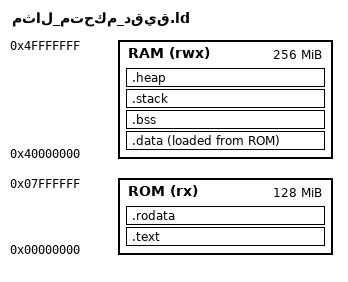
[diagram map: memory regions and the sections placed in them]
/* ════════════════════════════════════════════════════════════════════════════
   مثال_متحكم_دقيق.ld — سكريبت رابط لـ QEMU ARM virt
   ════════════════════════════════════════════════════════════════════════════

   خريطة الذاكرة لـ QEMU -machine virt:
   ────────────────────────────────────────────────────────────────────────
     0x00000000 - 0x07FFFFFF : Flash/ROM (كود وبيانات ثابتة)
     0x08000000 - 0x0801FFFF : GIC Distributor & CPU Interface
     0x09000000 - 0x09000FFF : UART0 PL011
     0x40000000 - 0x4FFFFFFF : DRAM (256 MB) — المكدّس والكومة

   طريقة الاستخدام:
   ────────────────────────────────────────────────────────────────────────
     aarch64-none-elf-ld مثال_متحكم_دقيق.o -T مثال_متحكم_دقيق.ld -o مثال_متحكم_دقيق.elf

   ════════════════════════════════════════════════════════════════════════════ */

/* ── إخبار الرابط بنقطة الدخول ────────────────────────────────────────────
   يجب أن يتطابق مع اسم الدالة المُزيَّنة بـ #[نقطة_دخول] في الكود */
ENTRY(_start)

/* ── خريطة الذاكرة للجهاز ──────────────────────────────────────────────── */
MEMORY {
    /*
     * ROM: ذاكرة القراءة فقط — تحتوي الكود وبيانات .rodata
     * rx = قراءة + تنفيذ (بدون كتابة)
     * الحجم: 128 ميغابايت
     */
    ROM (rx)  : ORIGIN = 0x00000000, LENGTH = 0x08000000

    /*
     * RAM: ذاكرة القراءة والكتابة — .data و.bss والمكدّس
     * رwx = قراءة + كتابة + تنفيذ
     * الحجم: 256 ميغابايت (QEMU virt default)
     */
    RAM (rwx) : ORIGIN = 0x40000000, LENGTH = 0x10000000
}

/* ── المقاطع (Sections) ────────────────────────────────────────────────── */
SECTIONS {

    /* ── .text: الكود القابل للتنفيذ ─────────────────────────────────────
       يُوضع في ROM عند العنوان 0x00000000 */
    .text : {
        /* نقطة البداية — يجب أن تكون أولاً */
        KEEP(*(.text._start))
        KEEP(*(.text.start))

        /* بقية الكود */
        *(.text)
        *(.text.*)

        /* جداول المقاطعات (لو وُجدت) */
        KEEP(*(.vectors))
        KEEP(*(.interrupt_vector_table))

        /* محاذاة 16 بايت لنهاية قطعة .text */
        . = ALIGN(16);
    } > ROM

    /* ── .rodata: البيانات الثابتة للقراءة فقط ──────────────────────────
       السلاسل النصية (الرسائل على UART)، الثوابت، جداول البحث */
    .rodata : {
        *(.rodata)
        *(.rodata.*)
        . = ALIGN(8);
    } > ROM

    /* ── .data: البيانات المُهيَّأة ──────────────────────────────────────
       المتغيرات التي لها قيمة أولية != 0
       تُخزَّن في ROM ثم تُنسَخ إلى RAM عند الإقلاع */
    .data : {
        __data_start = .;          /* رمز بداية .data في RAM */
        *(.data)
        *(.data.*)
        . = ALIGN(8);
        __data_end = .;            /* رمز نهاية .data في RAM */
    } > RAM AT > ROM               /* التحميل من ROM، التشغيل في RAM */

    /* رمز للكود لمعرفة أين تبدأ .data في ROM (للنسخ) */
    __data_load_start = LOADADDR(.data);

    /* ── .bss: البيانات المُهيَّأة بصفر ─────────────────────────────────
       المتغيرات العالمية والثابتة = 0
       يجب تصفيرها يدوياً في _start (لأن freestanding لا يملك CRT) */
    .bss (NOLOAD) : {
        __bss_start = .;           /* رمز تستخدمه تصفير_BSS() في الكود */
        *(.bss)
        *(.bss.*)
        *(COMMON)
        . = ALIGN(8);
        __bss_end = .;             /* رمز نهاية BSS */
    } > RAM

    /* ── المكدّس (Stack) ────────────────────────────────────────────────
       يبدأ من أعلى RAM وينمو لأسفل
       الحجم: 64 كيلوبايت (كافٍ لهذا المثال) */
    .stack (NOLOAD) : {
        . = ALIGN(16);
        __stack_bottom = .;        /* نهاية المكدّس (أدنى عنوان) */
        . += 0x10000;              /* 64 كيلوبايت */
        __stack_top = .;           /* قمة المكدّس (أعلى عنوان — نقطة البداية) */
    } > RAM

    /* ── الكومة (Heap) — لا تُستخدم بدون مخصّص ──────────────────────────
       محجوزة هنا للمستقبل إذا أُضيف مخصّص ذاكرة */
    .heap (NOLOAD) : {
        __heap_start = .;
        . = ALIGN(8);
    } > RAM

    /* ── رموز مفيدة للكود ───────────────────────────────────────────────
       يمكن استخدامها في الكود عبر: extern "C" uint8_t __heap_start[]; */
    __heap_end = ORIGIN(RAM) + LENGTH(RAM);

    /* ── التخلص من المقاطع غير الضرورية ────────────────────────────────
       هذه المقاطع لا معنى لها في freestanding */
    /DISCARD/ : {
        *(.note.GNU-stack)         /* علامات تنفيذية لـ GNU */
        *(.eh_frame)               /* معلومات معالجة الاستثناءات C++ */
        *(.gcc_except_table)       /* جداول استثناءات GCC */
        *(.comment)                /* تعليقات المترجم */
    }
}
